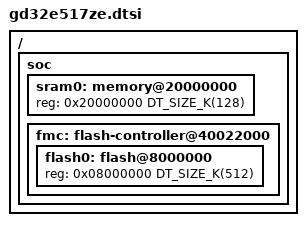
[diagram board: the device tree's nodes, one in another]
/*
 * Copyright (c) 2025, GigaDevice Semiconductor Inc.
 *
 * SPDX-License-Identifier: Apache-2.0
 */

#include <mem.h>
#include <gd/gd32e51x/gd32e51x.dtsi>

/ {
	soc {
		sram0: memory@20000000 {
			reg = <0x20000000 DT_SIZE_K(128)>;
		};

		fmc: flash-controller@40022000 {
			flash0: flash@8000000 {
				reg = <0x08000000 DT_SIZE_K(512)>;
			};
		};
	};
};
